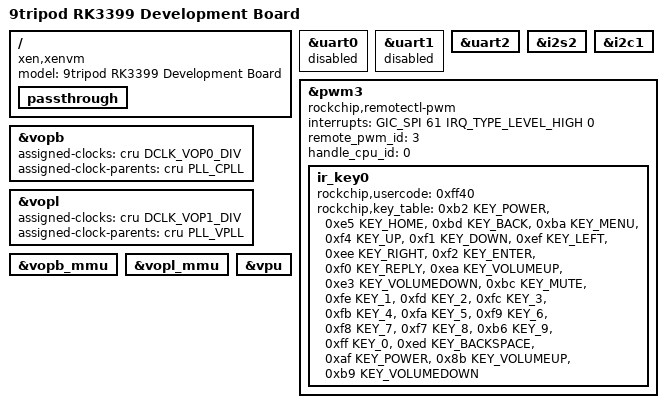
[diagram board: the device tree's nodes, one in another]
/*
 * Copyright (c) 2016 Fuzhou Rockchip Electronics Co., Ltd
 *
 * This file is dual-licensed: you can use it either under the terms
 * of the GPL or the X11 license, at your option. Note that this dual
 * licensing only applies to this file, and not this project as a
 * whole.
 *
 *  a) This file is free software; you can redistribute it and/or
 *     modify it under the terms of the GNU General Public License as
 *     published by the Free Software Foundation; either version 2 of the
 *     License, or (at your option) any later version.
 *
 *     This file is distributed in the hope that it will be useful,
 *     but WITHOUT ANY WARRANTY; without even the implied warranty of
 *     MERCHANTABILITY or FITNESS FOR A PARTICULAR PURPOSE.  See the
 *     GNU General Public License for more details.
 *
 * Or, alternatively,
 *
 *  b) Permission is hereby granted, free of charge, to any person
 *     obtaining a copy of this software and associated documentation
 *     files (the "Software"), to deal in the Software without
 *     restriction, including without limitation the rights to use,
 *     copy, modify, merge, publish, distribute, sublicense, and/or
 *     sell copies of the Software, and to permit persons to whom the
 *     Software is furnished to do so, subject to the following
 *     conditions:
 *
 *     The above copyright notice and this permission notice shall be
 *     included in all copies or substantial portions of the Software.
 *
 *     THE SOFTWARE IS PROVIDED "AS IS", WITHOUT WARRANTY OF ANY KIND,
 *     EXPRESS OR IMPLIED, INCLUDING BUT NOT LIMITED TO THE WARRANTIES
 *     OF MERCHANTABILITY, FITNESS FOR A PARTICULAR PURPOSE AND
 *     NONINFRINGEMENT. IN NO EVENT SHALL THE AUTHORS OR COPYRIGHT
 *     HOLDERS BE LIABLE FOR ANY CLAIM, DAMAGES OR OTHER LIABILITY,
 *     WHETHER IN AN ACTION OF CONTRACT, TORT OR OTHERWISE, ARISING
 *     FROM, OUT OF OR IN CONNECTION WITH THE SOFTWARE OR THE USE OR
 *     OTHER DEALINGS IN THE SOFTWARE.
 */

/dts-v1/;

#include <dt-bindings/input/input.h>
#include "x3399-baseboard.dtsi"
#include "rk3399-android.dtsi"
#include "rk3399-vop-clk-set.dtsi"

/ {
	model = "9tripod RK3399 Development Board";
	compatible = "xen,xenvm";
	passthrough {
	};
};

&uart0 {
	status = "disabled";
};

&uart1 {
	status = "disabled";
};

&uart2 {
	status = "okay";
};

&i2s2 {
	status = "okay";
};

&i2c1 {
	status = "okay";
};

&pwm3 {
	status = "okay";
	interrupts = <GIC_SPI 61 IRQ_TYPE_LEVEL_HIGH 0>;
	compatible = "rockchip,remotectl-pwm";
	remote_pwm_id = <3>;
	handle_cpu_id = <0>;

	ir_key0 {
		rockchip,usercode = <0xff40>;
		rockchip,key_table =
			<0xb2	KEY_POWER>,
			<0xe5	KEY_HOME>,
			<0xbd	KEY_BACK>,
			<0xba	KEY_MENU>,
			<0xf4	KEY_UP>,
			<0xf1	KEY_DOWN>,
			<0xef	KEY_LEFT>,
			<0xee	KEY_RIGHT>,
			<0xf2	KEY_ENTER>,
			<0xf0	KEY_REPLY>,
			<0xea	KEY_VOLUMEUP>,
			<0xe3	KEY_VOLUMEDOWN>,
			<0xbc	KEY_MUTE>,
			<0xfe	KEY_1>,
			<0xfd	KEY_2>,
			<0xfc	KEY_3>,
			<0xfb	KEY_4>,
			<0xfa	KEY_5>,
			<0xf9	KEY_6>,
			<0xf8	KEY_7>,
			<0xf7	KEY_8>,
			<0xb6	KEY_9>,
			<0xff	KEY_0>,
			<0xed	KEY_BACKSPACE>,

			<0xaf	KEY_POWER>,
			<0x8b	KEY_VOLUMEUP>,
			<0xb9	KEY_VOLUMEDOWN>;
	};
};

&vopb {
	status = "okay";
	assigned-clocks = <&cru DCLK_VOP0_DIV>;
	assigned-clock-parents = <&cru PLL_CPLL>;
};

&vopl {
	status = "okay";
	assigned-clocks = <&cru DCLK_VOP1_DIV>;
	assigned-clock-parents = <&cru PLL_VPLL>;
};


&vopb_mmu {
	status = "okay";
};


&vopl_mmu {
	status = "okay";
};

&i2s2 {
	#sound-dai-cells = <0>;
};

&vpu {
	status = "okay";
};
